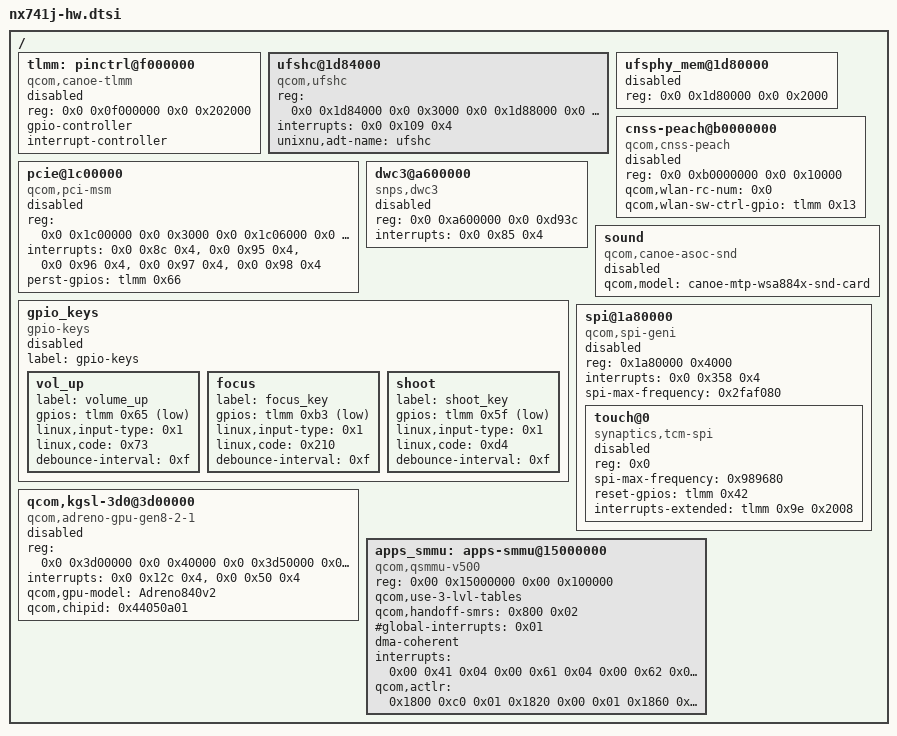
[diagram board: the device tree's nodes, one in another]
/*
 * NX741J hardware nodes copied from the device's own stock FDT
 * (stock/dt/live_fdt.dtb, SHA-256 a5c109c0…). These nodes are status="disabled":
 * they document the real register/IRQ/GPIO values for driver bring-up and do not
 * claim the Linux drivers are ported. Clock/regulator/SMMU phandles are omitted on
 * purpose so the fragment compiles against the minimal sm8850.dtsi.
 */

/ {
    tlmm: pinctrl@f000000 {
        compatible = "qcom,canoe-tlmm";
        reg = <0x0 0x0f000000 0x0 0x202000>;
        gpio-controller;
        #gpio-cells = <0x2>;
        interrupt-controller;
        #interrupt-cells = <0x2>;
        status = "disabled";
    };

    ufshc@1d84000 {
        compatible = "qcom,ufshc";
        reg = <0x0 0x1d84000 0x0 0x3000
               0x0 0x1d88000 0x0 0x18000
               0x0 0x1da5000 0x0 0x2000
               0x0 0x1da4000 0x0 0x10>;
        reg-names = "ufs_mem", "ice", "mcq_sqd", "mcq_vs";
        interrupts = <0x0 0x109 0x4>;
        unixnu,adt-name = "ufshc";
        status = "okay";
    };

    ufsphy_mem@1d80000 {
        reg = <0x0 0x1d80000 0x0 0x2000>;
        reg-names = "phy_mem";
        #phy-cells = <0x0>;
        status = "disabled";
    };

    pcie@1c00000 {
        compatible = "qcom,pci-msm";
        reg = <0x0 0x1c00000 0x0 0x3000
               0x0 0x1c06000 0x0 0x2000
               0x4 0x0 0x0 0x10000000
               0x4 0xf20 0x0 0xa8
               0x4 0x10000000 0x0 0x1000
               0x0 0x1d07000 0x0 0x7000>;
        reg-names = "parf", "phy", "dm_core", "elbi", "iatu", "pcie_sm";
        #address-cells = <0x3>;
        #size-cells = <0x2>;
        ranges = <0x1000000 0x0 0x40200000 0x0 0x40200000 0x0 0x100000
                  0x2000000 0x0 0x40300000 0x0 0x40300000 0x0 0x3d00000
                  0x43000000 0x4 0x10100000 0x4 0x10100000 0x2 0xeff00000>;
        interrupts = <0x0 0x8c 0x4>, <0x0 0x95 0x4>, <0x0 0x96 0x4>,
                     <0x0 0x97 0x4>, <0x0 0x98 0x4>;
        interrupt-names = "int_global_int", "int_a", "int_b", "int_c", "int_d";
        perst-gpios = <&tlmm 0x66 0x0>;
        status = "disabled";
    };

    cnss-peach@b0000000 {
        compatible = "qcom,cnss-peach";
        reg = <0x0 0xb0000000 0x0 0x10000>;
        qcom,wlan-rc-num = <0x0>;
        qcom,wlan-sw-ctrl-gpio = <&tlmm 0x13 0x0>;
        status = "disabled";
    };

    dwc3@a600000 {
        compatible = "snps,dwc3";
        reg = <0x0 0xa600000 0x0 0xd93c>;
        interrupts = <0x0 0x85 0x4>;
        status = "disabled";
    };

    gpio_keys {
        compatible = "gpio-keys";
        label = "gpio-keys";
        status = "disabled";

        vol_up {
            label = "volume_up";
            gpios = <&tlmm 0x65 0x1>;
            linux,input-type = <0x1>;
            linux,code = <0x73>;
            debounce-interval = <0xf>;
        };
        focus {
            label = "focus_key";
            gpios = <&tlmm 0xb3 0x1>;
            linux,input-type = <0x1>;
            linux,code = <0x210>;
            debounce-interval = <0xf>;
        };
        shoot {
            label = "shoot_key";
            gpios = <&tlmm 0x5f 0x1>;
            linux,input-type = <0x1>;
            linux,code = <0xd4>;
            debounce-interval = <0xf>;
        };
    };

    sound {
        compatible = "qcom,canoe-asoc-snd";
        qcom,model = "canoe-mtp-wsa884x-snd-card";
        status = "disabled";
    };

    qcom,kgsl-3d0@3d00000 {
        compatible = "qcom,adreno-gpu-gen8-2-1";
        reg = <0x0 0x3d00000 0x0 0x40000
               0x0 0x3d50000 0x0 0x10000
               0x0 0x3d61000 0x0 0x3000
               0x0 0x3d9e000 0x0 0x2000>;
        reg-names = "kgsl_3d0_reg_memory", "rscc", "cx_dbgc", "cx_misc";
        interrupts = <0x0 0x12c 0x4>, <0x0 0x50 0x4>;
        interrupt-names = "kgsl_3d0_irq", "cx_host_irq";
        qcom,gpu-model = "Adreno840v2";
        qcom,chipid = <0x44050a01>;
        status = "disabled";
    };

    spi@1a80000 {
        compatible = "qcom,spi-geni";
        reg = <0x1a80000 0x4000>;
        #address-cells = <0x1>;
        #size-cells = <0x0>;
        interrupts = <0x0 0x358 0x4>;
        spi-max-frequency = <0x2faf080>;
        status = "disabled";

        touch@0 {
            compatible = "synaptics,tcm-spi";
            reg = <0x0>;
            spi-max-frequency = <0x989680>;
            reset-gpios = <&tlmm 0x42 0x0>;
            interrupts-extended = <&tlmm 0x9e 0x2008>;
            status = "disabled";
        };
    };

	/*
	 * apps-smmu: Qualcomm implementation of the ARM MMU-500 (qsmmu-v500), taken
	 * from the stock FDT with the interrupt and ACTLR tables intact. ArmSmmu4K and
	 * the storage stack bind on the compatible; the display fragment references
	 * this node through the apps_smmu label.
	 */
	apps_smmu: apps-smmu@15000000 {
		compatible = "qcom,qsmmu-v500";
		reg = <0x00 0x15000000 0x00 0x100000>;
		#iommu-cells = <0x02>;
		qcom,use-3-lvl-tables;
		qcom,handoff-smrs = <0x800 0x02>;
		#global-interrupts = <0x01>;
		#size-cells = <0x02>;
		#address-cells = <0x02>;
		ranges;
		dma-coherent;
		interrupts = <0x00 0x41 0x04 0x00 0x61 0x04 0x00 0x62 0x04 0x00 0x63 0x04 0x00 0x64 0x04 0x00 0x65
				0x04 0x00 0x66 0x04 0x00 0x67 0x04 0x00 0x68 0x04 0x00 0x69 0x04 0x00 0x6a 0x04 0x00 0x6b 0x04 0x00
				0x6c 0x04 0x00 0x6d 0x04 0x00 0x6e 0x04 0x00 0x6f 0x04 0x00 0x70 0x04 0x00 0x71 0x04 0x00 0x72 0x04
				0x00 0x73 0x04 0x00 0x74 0x04 0x00 0x75 0x04 0x00 0x76 0x04 0x00 0xb5 0x04 0x00 0xb6 0x04 0x00 0xb7
				0x04 0x00 0xb8 0x04 0x00 0xb9 0x04 0x00 0xba 0x04 0x00 0xbb 0x04 0x00 0xbc 0x04 0x00 0xbd 0x04 0x00
				0xbe 0x04 0x00 0xbf 0x04 0x00 0xc0 0x04 0x00 0x13b 0x04 0x00 0x13c 0x04 0x00 0x13d 0x04 0x00 0x13e
				0x04 0x00 0x13f 0x04 0x00 0x140 0x04 0x00 0x141 0x04 0x00 0x142 0x04 0x00 0x143 0x04 0x00 0x144
				0x04 0x00 0x145 0x04 0x00 0x146 0x04 0x00 0x147 0x04 0x00 0x148 0x04 0x00 0x149 0x04 0x00 0x14a
				0x04 0x00 0x14b 0x04 0x00 0x14c 0x04 0x00 0x14d 0x04 0x00 0x14e 0x04 0x00 0x14f 0x04 0x00 0x150
				0x04 0x00 0x151 0x04 0x00 0x152 0x04 0x00 0x153 0x04 0x00 0x154 0x04 0x00 0x155 0x04 0x00 0x156
				0x04 0x00 0x157 0x04 0x00 0x158 0x04 0x00 0x159 0x04 0x00 0x18b 0x04 0x00 0x18c 0x04 0x00 0x18d
				0x04 0x00 0x18e 0x04 0x00 0x18f 0x04 0x00 0x190 0x04 0x00 0x191 0x04 0x00 0x192 0x04 0x00 0x193
				0x04 0x00 0x194 0x04 0x00 0x195 0x04 0x00 0x196 0x04 0x00 0x197 0x04 0x00 0x198 0x04 0x00 0x199
				0x04 0x00 0x1a2 0x04 0x00 0x1a3 0x04 0x00 0x19c 0x04 0x00 0x1a5 0x04 0x00 0x2c3 0x04 0x00 0x1a7
				0x04 0x00 0x1a8 0x04 0x00 0x1a9 0x04 0x00 0x2b2 0x04 0x00 0x2b3 0x04 0x00 0x2b4 0x04 0x00 0x2b5
				0x04 0x00 0x2b6 0x04 0x00 0x2b7 0x04 0x00 0x2b8 0x04 0x00 0x2b9 0x04 0x00 0x19a 0x04 0x00 0x1e8
				0x04 0x00 0x1e9 0x04 0x00 0x1ea 0x04 0x00 0x1eb 0x04 0x00 0x1ec 0x04 0x00 0x1ed 0x04 0x00 0x1ee
				0x04 0x00 0x1ef 0x04 0x00 0x1f0 0x04 0x00 0x1f1 0x04 0x00 0x1f2 0x04 0x00 0x1f3 0x04 0x00 0x1f4
				0x04 0x00 0x1f5 0x04 0x00 0x1f6 0x04>;
		qcom,actlr = <0x1800 0xc0 0x01 0x1820 0x00 0x01 0x1860 0x00 0x103 0x18a0 0x00 0x103 0x18e0 0x00 0x103
				0x1980 0x00 0x01 0x1c00 0x00 0x01 0xc01 0x40 0x303 0xc02 0x20 0x303 0xc03 0x40 0x303 0xc04 0x20
				0x303 0xc05 0x20 0x303 0xc06 0x20 0x303 0xc07 0x40 0x303 0xc08 0x20 0x303 0xc09 0x40 0x303 0xc0c
				0x40 0x303 0xc0d 0x40 0x303 0xc21 0x00 0x303 0xc23 0x00 0x303 0xc27 0x00 0x303 0xc29 0x00 0x303
				0xc2c 0x00 0x303 0xc2d 0x00 0x303 0xc42 0x00 0x303 0xc44 0x00 0x303 0xc45 0x00 0x303 0xc46 0x00
				0x303 0xc48 0x00 0x303 0x800 0x02 0x01 0x801 0x00 0x01 0x19a3 0x00 0x01 0x19a4 0x00 0x01 0x1900
				0x20 0x103 0x1904 0x20 0x103 0x1923 0x00 0x103 0x1940 0x00 0x103 0x1941 0x00 0x103 0x1943 0x00
				0x103 0x1944 0x00 0x103 0x1945 0x00 0x103 0x1946 0x00 0x103 0x1a20 0x00 0x103 0x1a21 0x00 0x103>;
		status = "ok";
	};
};
